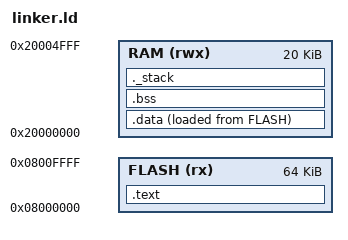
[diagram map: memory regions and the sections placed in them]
/**
 * Linker script for STM32F103C8T6
 * Flash: 64KB @ 0x08000000
 * RAM:   20KB @ 0x20000000
 */

ENTRY(Reset_Handler)

MEMORY
{
    FLASH (rx)  : ORIGIN = 0x08000000, LENGTH = 64K
    RAM (rwx)   : ORIGIN = 0x20000000, LENGTH = 20K
}

_stack_size = 0x400;

SECTIONS
{
    .text :
    {
        . = ALIGN(4);
        KEEP(*(.isr_vector))
        *(.text)
        *(.text*)
        *(.rodata)
        *(.rodata*)
        . = ALIGN(4);
        _etext = .;
    } > FLASH

    _sidata = LOADADDR(.data);
    .data :
    {
        . = ALIGN(4);
        _sdata = .;
        *(.data)
        *(.data*)
        . = ALIGN(4);
        _edata = .;
    } > RAM AT > FLASH

    .bss :
    {
        . = ALIGN(4);
        _sbss = .;
        *(.bss)
        *(.bss*)
        *(COMMON)
        . = ALIGN(4);
        _ebss = .;
    } > RAM

    ._stack :
    {
        . = ALIGN(8);
        . = . + _stack_size;
        . = ALIGN(8);
        _estack = .;
    } > RAM
}
